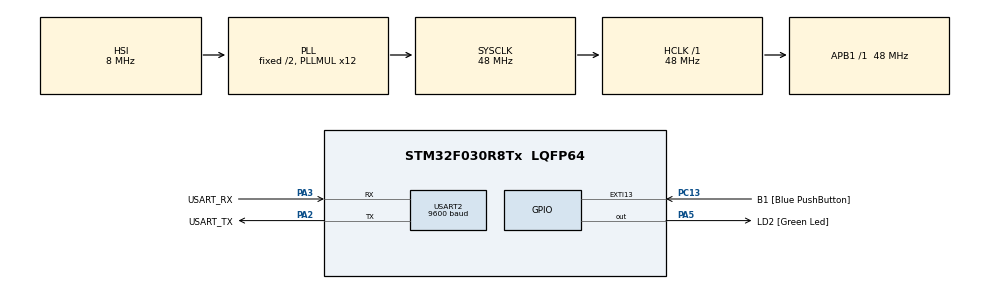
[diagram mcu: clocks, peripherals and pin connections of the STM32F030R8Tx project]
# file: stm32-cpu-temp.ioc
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ADC.ContinuousConvMode=ENABLE
ADC.DMAContinuousRequests=ENABLE
ADC.EOCSelection=ADC_EOC_SEQ_CONV
ADC.ExternalTrigConv=ADC_SOFTWARE_START
ADC.SamplingTime=ADC_SAMPLETIME_239CYCLES_5
Dma.ADC.0.Direction=DMA_PERIPH_TO_MEMORY
Dma.ADC.0.Instance=DMA1_Channel1
Dma.ADC.0.MemDataAlignment=DMA_MDATAALIGN_HALFWORD
Dma.ADC.0.MemInc=DMA_MINC_ENABLE
Dma.ADC.0.Mode=DMA_CIRCULAR
Dma.ADC.0.PeriphDataAlignment=DMA_PDATAALIGN_HALFWORD
Dma.ADC.0.PeriphInc=DMA_PINC_DISABLE
Dma.ADC.0.Priority=DMA_PRIORITY_LOW
Dma.Request0=ADC
Mcu.Family=STM32F0
Mcu.Name=STM32F030R8Tx
Mcu.Package=LQFP64
NVIC.ADC1_IRQn=true\:0\:0\:false\:false\:true\:true\:true\:true
NVIC.DMA1_Channel1_IRQn=true\:0\:0\:false\:false\:true\:false\:true\:true
NVIC.USART2_IRQn=true\:0\:0\:false\:false\:true\:true\:true\:true
PA13.GPIO_Label=TMS
PA13.Mode=Serial_Wire
PA13.Signal=SYS_SWDIO
PA14.GPIO_Label=TCK
PA14.Mode=Serial_Wire
PA14.Signal=SYS_SWCLK
PA2.GPIO_Label=USART_TX
PA2.GPIO_Mode=GPIO_MODE_AF_PP
PA2.GPIO_PuPd=GPIO_NOPULL
PA2.GPIO_Speed=GPIO_SPEED_FREQ_LOW
PA2.Mode=Asynchronous
PA2.Signal=USART2_TX
PA3.GPIO_Label=USART_RX
PA3.GPIO_Mode=GPIO_MODE_AF_PP
PA3.GPIO_PuPd=GPIO_NOPULL
PA3.GPIO_Speed=GPIO_SPEED_FREQ_LOW
PA3.Mode=Asynchronous
PA3.Signal=USART2_RX
PA5.GPIO_Label=LD2 [Green Led]
PA5.GPIO_Mode=GPIO_MODE_OUTPUT_PP
PA5.GPIO_PuPd=GPIO_NOPULL
PA5.GPIO_Speed=GPIO_SPEED_FREQ_LOW
PA5.Signal=GPIO_Output
PC13.GPIO_Label=B1 [Blue PushButton]
PC13.GPIO_ModeDefaultEXTI=GPIO_MODE_IT_FALLING
PC13.Signal=GPXTI13
PC14-OSC32_IN.Mode=LSE-External-Oscillator
PC14-OSC32_IN.Signal=RCC_OSC32_IN
PC15-OSC32_OUT.Mode=LSE-External-Oscillator
PC15-OSC32_OUT.Signal=RCC_OSC32_OUT
PF0-OSC_IN.Mode=HSE-External-Clock-Source
PF0-OSC_IN.Signal=RCC_OSC_IN
PF1-OSC_OUT.Signal=RCC_OSC_OUT
ProjectManager.HeapSize=0x200
ProjectManager.StackSize=0x400
ProjectManager.TargetToolchain=CMake
RCC.AHBFreq_Value=48000000
RCC.APB1Freq_Value=48000000
RCC.APB1TimFreq_Value=48000000
RCC.HCLKFreq_Value=48000000
RCC.PLLMUL=RCC_PLL_MUL12
RCC.SYSCLKFreq_VALUE=48000000
RCC.SYSCLKSource=RCC_SYSCLKSOURCE_PLLCLK
USART2.BaudRate=9600
USART2.VirtualMode-Asynchronous=VM_ASYNC
VP_ADC_TempSens_Input.Mode=IN-TempSens
VP_ADC_Vref_Input.Mode=IN-Vrefint
VP_CRC_VS_CRC.Mode=CRC_Activate
board=NUCLEO-F030R8

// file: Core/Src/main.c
/* USER CODE BEGIN Header */
/**
  ******************************************************************************
  * @file           : main.c
  * @brief          : Main program body
  ******************************************************************************
  * @attention
  *
  * Copyright (c) 2025 STMicroelectronics.
  * All rights reserved.
  *
  * This software is licensed under terms that can be found in the LICENSE file
  * in the root directory of this software component.
  * If no LICENSE file comes with this software, it is provided AS-IS.
  *
  ******************************************************************************
  */
/* USER CODE END Header */
#include "main.h"

/* USER CODE BEGIN Includes */
#include <app.h>
/* USER CODE END Includes */

ADC_HandleTypeDef hadc;
DMA_HandleTypeDef hdma_adc;

CRC_HandleTypeDef hcrc;

void SystemClock_Config(void);
static void MX_GPIO_Init(void);
static void MX_DMA_Init(void);
static void MX_ADC_Init(void);
static void MX_CRC_Init(void);
static void MX_USART2_UART_Init(void);

int main(void)
{

  /* MCU Configuration--------------------------------------------------------*/

  /* Reset of all peripherals, Initializes the Flash interface and the Systick. */
  HAL_Init();

  /* Configure the system clock */
  SystemClock_Config();

  /* Initialize all configured peripherals */
  MX_GPIO_Init();
  MX_DMA_Init();
  MX_ADC_Init();
  MX_CRC_Init();
  MX_USART2_UART_Init();

  /* Infinite loop */
  /* USER CODE BEGIN WHILE */
  mainLoop();
    /* USER CODE END WHILE */

}

void SystemClock_Config(void)
{
  RCC_OscInitTypeDef RCC_OscInitStruct = {0};
  RCC_ClkInitTypeDef RCC_ClkInitStruct = {0};

  /** Initializes the RCC Oscillators according to the specified parameters
  * in the RCC_OscInitTypeDef structure.
  */
  RCC_OscInitStruct.OscillatorType = RCC_OSCILLATORTYPE_HSI|RCC_OSCILLATORTYPE_HSI14;
  RCC_OscInitStruct.HSIState = RCC_HSI_ON;
  RCC_OscInitStruct.HSI14State = RCC_HSI14_ON;
  RCC_OscInitStruct.HSICalibrationValue = RCC_HSICALIBRATION_DEFAULT;
  RCC_OscInitStruct.HSI14CalibrationValue = 16;
  RCC_OscInitStruct.PLL.PLLState = RCC_PLL_ON;
  RCC_OscInitStruct.PLL.PLLSource = RCC_PLLSOURCE_HSI;
  RCC_OscInitStruct.PLL.PLLMUL = RCC_PLL_MUL12;
  RCC_OscInitStruct.PLL.PREDIV = RCC_PREDIV_DIV1;
  if (HAL_RCC_OscConfig(&RCC_OscInitStruct) != HAL_OK)
  {
    Error_Handler();
  }

  /** Initializes the CPU, AHB and APB buses clocks
  */
  RCC_ClkInitStruct.ClockType = RCC_CLOCKTYPE_HCLK|RCC_CLOCKTYPE_SYSCLK
                              |RCC_CLOCKTYPE_PCLK1;
  RCC_ClkInitStruct.SYSCLKSource = RCC_SYSCLKSOURCE_PLLCLK;
  RCC_ClkInitStruct.AHBCLKDivider = RCC_SYSCLK_DIV1;
  RCC_ClkInitStruct.APB1CLKDivider = RCC_HCLK_DIV1;

  if (HAL_RCC_ClockConfig(&RCC_ClkInitStruct, FLASH_LATENCY_1) != HAL_OK)
  {
    Error_Handler();
  }
}

static void MX_ADC_Init(void)
{

  ADC_ChannelConfTypeDef sConfig = {0};

  /** Configure the global features of the ADC (Clock, Resolution, Data Alignment and number of conversion)
  */
  hadc.Instance = ADC1;
  hadc.Init.ClockPrescaler = ADC_CLOCK_ASYNC_DIV1;
  hadc.Init.Resolution = ADC_RESOLUTION_12B;
  hadc.Init.DataAlign = ADC_DATAALIGN_RIGHT;
  hadc.Init.ScanConvMode = ADC_SCAN_DIRECTION_FORWARD;
  hadc.Init.EOCSelection = ADC_EOC_SEQ_CONV;
  hadc.Init.LowPowerAutoWait = DISABLE;
  hadc.Init.LowPowerAutoPowerOff = DISABLE;
  hadc.Init.ContinuousConvMode = ENABLE;
  hadc.Init.DiscontinuousConvMode = DISABLE;
  hadc.Init.ExternalTrigConv = ADC_SOFTWARE_START;
  hadc.Init.ExternalTrigConvEdge = ADC_EXTERNALTRIGCONVEDGE_NONE;
  hadc.Init.DMAContinuousRequests = ENABLE;
  hadc.Init.Overrun = ADC_OVR_DATA_PRESERVED;
  if (HAL_ADC_Init(&hadc) != HAL_OK)
  {
    Error_Handler();
  }

  /** Configure for the selected ADC regular channel to be converted.
  */
  sConfig.Channel = ADC_CHANNEL_TEMPSENSOR;
  sConfig.Rank = ADC_RANK_CHANNEL_NUMBER;
  sConfig.SamplingTime = ADC_SAMPLETIME_239CYCLES_5;
  if (HAL_ADC_ConfigChannel(&hadc, &sConfig) != HAL_OK)
  {
    Error_Handler();
  }

  /** Configure for the selected ADC regular channel to be converted.
  */
  sConfig.Channel = ADC_CHANNEL_VREFINT;
  if (HAL_ADC_ConfigChannel(&hadc, &sConfig) != HAL_OK)
  {
    Error_Handler();
  }

}

static void MX_CRC_Init(void)
{

  hcrc.Instance = CRC;
  hcrc.Init.DefaultInitValueUse = DEFAULT_INIT_VALUE_ENABLE;
  hcrc.Init.InputDataInversionMode = CRC_INPUTDATA_INVERSION_NONE;
  hcrc.Init.OutputDataInversionMode = CRC_OUTPUTDATA_INVERSION_DISABLE;
  hcrc.InputDataFormat = CRC_INPUTDATA_FORMAT_BYTES;
  if (HAL_CRC_Init(&hcrc) != HAL_OK)
  {
    Error_Handler();
  }

}

static void MX_USART2_UART_Init(void)
{

  LL_USART_InitTypeDef USART_InitStruct = {0};

  LL_GPIO_InitTypeDef GPIO_InitStruct = {0};

  /* Peripheral clock enable */
  LL_APB1_GRP1_EnableClock(LL_APB1_GRP1_PERIPH_USART2);

  LL_AHB1_GRP1_EnableClock(LL_AHB1_GRP1_PERIPH_GPIOA);
  /**USART2 GPIO Configuration
  PA2   ------> USART2_TX
  PA3   ------> USART2_RX
  */
  GPIO_InitStruct.Pin = LL_GPIO_PIN_2;
  GPIO_InitStruct.Mode = LL_GPIO_MODE_ALTERNATE;
  GPIO_InitStruct.Speed = LL_GPIO_SPEED_FREQ_LOW;
  GPIO_InitStruct.OutputType = LL_GPIO_OUTPUT_PUSHPULL;
  GPIO_InitStruct.Pull = LL_GPIO_PULL_NO;
  GPIO_InitStruct.Alternate = LL_GPIO_AF_1;
  LL_GPIO_Init(GPIOA, &GPIO_InitStruct);

  GPIO_InitStruct.Pin = LL_GPIO_PIN_3;
  GPIO_InitStruct.Mode = LL_GPIO_MODE_ALTERNATE;
  GPIO_InitStruct.Speed = LL_GPIO_SPEED_FREQ_LOW;
  GPIO_InitStruct.OutputType = LL_GPIO_OUTPUT_PUSHPULL;
  GPIO_InitStruct.Pull = LL_GPIO_PULL_NO;
  GPIO_InitStruct.Alternate = LL_GPIO_AF_1;
  LL_GPIO_Init(GPIOA, &GPIO_InitStruct);

  /* USART2 interrupt Init */
  NVIC_SetPriority(USART2_IRQn, 0);
  NVIC_EnableIRQ(USART2_IRQn);

  USART_InitStruct.BaudRate = 9600;
  USART_InitStruct.DataWidth = LL_USART_DATAWIDTH_8B;
  USART_InitStruct.StopBits = LL_USART_STOPBITS_1;
  USART_InitStruct.Parity = LL_USART_PARITY_NONE;
  USART_InitStruct.TransferDirection = LL_USART_DIRECTION_TX_RX;
  USART_InitStruct.HardwareFlowControl = LL_USART_HWCONTROL_NONE;
  USART_InitStruct.OverSampling = LL_USART_OVERSAMPLING_16;
  LL_USART_Init(USART2, &USART_InitStruct);
  LL_USART_DisableIT_CTS(USART2);
  LL_USART_ConfigAsyncMode(USART2);
  LL_USART_Enable(USART2);
  /* USER CODE BEGIN USART2_Init 2 */
  LL_USART_EnableIT_RXNE(USART2);
  /* USER CODE END USART2_Init 2 */

}

static void MX_DMA_Init(void)
{

  /* DMA controller clock enable */
  __HAL_RCC_DMA1_CLK_ENABLE();

  /* DMA interrupt init */
  /* DMA1_Channel1_IRQn interrupt configuration */
  HAL_NVIC_SetPriority(DMA1_Channel1_IRQn, 0, 0);
  HAL_NVIC_EnableIRQ(DMA1_Channel1_IRQn);

}

static void MX_GPIO_Init(void)
{
  GPIO_InitTypeDef GPIO_InitStruct = {0};

  /* GPIO Ports Clock Enable */
  __HAL_RCC_GPIOC_CLK_ENABLE();
  __HAL_RCC_GPIOF_CLK_ENABLE();
  __HAL_RCC_GPIOA_CLK_ENABLE();

  /*Configure GPIO pin Output Level */
  HAL_GPIO_WritePin(LD2_GPIO_Port, LD2_Pin, GPIO_PIN_RESET);

  /*Configure GPIO pin : B1_Pin */
  GPIO_InitStruct.Pin = B1_Pin;
  GPIO_InitStruct.Mode = GPIO_MODE_IT_FALLING;
  GPIO_InitStruct.Pull = GPIO_NOPULL;
  HAL_GPIO_Init(B1_GPIO_Port, &GPIO_InitStruct);

  /*Configure GPIO pin : LD2_Pin */
  GPIO_InitStruct.Pin = LD2_Pin;
  GPIO_InitStruct.Mode = GPIO_MODE_OUTPUT_PP;
  GPIO_InitStruct.Pull = GPIO_NOPULL;
  GPIO_InitStruct.Speed = GPIO_SPEED_FREQ_LOW;
  HAL_GPIO_Init(LD2_GPIO_Port, &GPIO_InitStruct);

}

void Error_Handler(void)
{
  __disable_irq();
  while (1)
  {
  }
}
